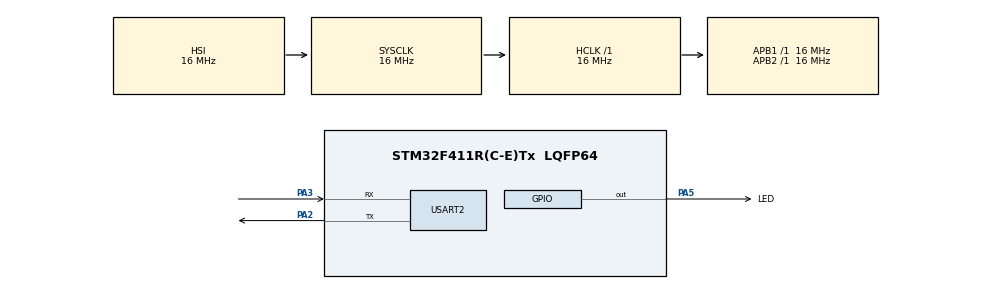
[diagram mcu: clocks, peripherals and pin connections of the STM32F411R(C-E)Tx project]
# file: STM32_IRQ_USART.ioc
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Mcu.Family=STM32F4
Mcu.Name=STM32F411R(C-E)Tx
Mcu.Package=LQFP64
NVIC.PriorityGroup=NVIC_PRIORITYGROUP_4
NVIC.USART2_IRQn=true\:0\:0\:false\:false\:true\:true\:true\:true
PA2.Mode=Asynchronous
PA2.Signal=USART2_TX
PA3.Mode=Asynchronous
PA3.Signal=USART2_RX
PA5.GPIO_Label=LED
PA5.Signal=GPIO_Output
ProjectManager.HeapSize=0x200
ProjectManager.StackSize=0x400
ProjectManager.TargetToolchain=STM32CubeIDE
RCC.AHBFreq_Value=16000000
RCC.APB1Freq_Value=16000000
RCC.APB2Freq_Value=16000000
RCC.CortexFreq_Value=16000000
RCC.HSE_VALUE=25000000
RCC.HSI_VALUE=16000000
RCC.LSE_VALUE=32768
RCC.SYSCLKFreq_VALUE=16000000
RCC.VCOOutputFreq_Value=192000000
TIM2.Prescaler=16-1
USART2.VirtualMode=VM_ASYNC
VP_TIM2_VS_ClockSourceINT.Mode=Internal
board=custom

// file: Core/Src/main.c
/* USER CODE BEGIN Header */
/**
  ******************************************************************************
  * @file           : main.c
  * @brief          : Main program body
  ******************************************************************************
  * @attention
  *
  * Copyright (c) 2026 STMicroelectronics.
  * All rights reserved.
  *
  * This software is licensed under terms that can be found in the LICENSE file
  * in the root directory of this software component.
  * If no LICENSE file comes with this software, it is provided AS-IS.
  *
  ******************************************************************************
  */
/* USER CODE END Header */
#include "main.h"
#include "tim.h"
#include "usart.h"
#include "gpio.h"

/* USER CODE BEGIN Includes */
#include <stdio.h>
#include <string.h>
/* USER CODE END Includes */

/* USER CODE BEGIN PV */
uint32_t start_time = 0;
uint32_t end_time = 0;
uint32_t elapsed_time = 0;

uint8_t uart_tx_done = 1;
/* USER CODE END PV */

void SystemClock_Config(void);

/* USER CODE BEGIN 0 */
int _write(int file, char *ptr, int len)
{
  HAL_UART_Transmit(&huart2, (uint8_t *)ptr, len, 0xFFFF);
  return len;
}
void HAL_UART_TxCpltCallback(UART_HandleTypeDef *huart)
{
  uart_tx_done = 1;
}
void UART_Send_IT(char *message)
{
    uart_tx_done = 0;

    HAL_UART_Transmit_IT(&huart2,(uint8_t *)message,strlen(message));
}
/* USER CODE END 0 */

int main(void)
{

  /* MCU Configuration--------------------------------------------------------*/

  /* Reset of all peripherals, Initializes the Flash interface and the Systick. */
  HAL_Init();

  /* Configure the system clock */
  SystemClock_Config();

  /* Initialize all configured peripherals */
  MX_GPIO_Init();
  MX_USART2_UART_Init();
  MX_TIM2_Init();
  /* USER CODE BEGIN 2 */
  HAL_TIM_Base_Start(&htim2);
  /* USER CODE END 2 */

  /* Infinite loop */
  /* USER CODE BEGIN WHILE */
  while (1)
  {
    if(uart_tx_done==1)
    {
      HAL_GPIO_WritePin(LED_GPIO_Port, LED_Pin, GPIO_PIN_SET);
      start_time = __HAL_TIM_GET_COUNTER(&htim2);
      //printf("This is a test message from STM32 using USART2!!!\r\n");
      UART_Send_IT("This is a test message from STM32 using USART2!!!\r\n");
      end_time = __HAL_TIM_GET_COUNTER(&htim2);
      HAL_GPIO_WritePin(LED_GPIO_Port, LED_Pin, GPIO_PIN_RESET);
      elapsed_time = end_time - start_time;
    }
    HAL_Delay(20);
    /* USER CODE END WHILE */

  }
}

void SystemClock_Config(void)
{
  RCC_OscInitTypeDef RCC_OscInitStruct = {0};
  RCC_ClkInitTypeDef RCC_ClkInitStruct = {0};

  /** Configure the main internal regulator output voltage
  */
  __HAL_RCC_PWR_CLK_ENABLE();
  __HAL_PWR_VOLTAGESCALING_CONFIG(PWR_REGULATOR_VOLTAGE_SCALE1);

  /** Initializes the RCC Oscillators according to the specified parameters
  * in the RCC_OscInitTypeDef structure.
  */
  RCC_OscInitStruct.OscillatorType = RCC_OSCILLATORTYPE_HSI;
  RCC_OscInitStruct.HSIState = RCC_HSI_ON;
  RCC_OscInitStruct.HSICalibrationValue = RCC_HSICALIBRATION_DEFAULT;
  RCC_OscInitStruct.PLL.PLLState = RCC_PLL_NONE;
  if (HAL_RCC_OscConfig(&RCC_OscInitStruct) != HAL_OK)
  {
    Error_Handler();
  }

  /** Initializes the CPU, AHB and APB buses clocks
  */
  RCC_ClkInitStruct.ClockType = RCC_CLOCKTYPE_HCLK|RCC_CLOCKTYPE_SYSCLK
                              |RCC_CLOCKTYPE_PCLK1|RCC_CLOCKTYPE_PCLK2;
  RCC_ClkInitStruct.SYSCLKSource = RCC_SYSCLKSOURCE_HSI;
  RCC_ClkInitStruct.AHBCLKDivider = RCC_SYSCLK_DIV1;
  RCC_ClkInitStruct.APB1CLKDivider = RCC_HCLK_DIV1;
  RCC_ClkInitStruct.APB2CLKDivider = RCC_HCLK_DIV1;

  if (HAL_RCC_ClockConfig(&RCC_ClkInitStruct, FLASH_LATENCY_0) != HAL_OK)
  {
    Error_Handler();
  }
}

void Error_Handler(void)
{
  __disable_irq();
  while (1)
  {
  }
}
